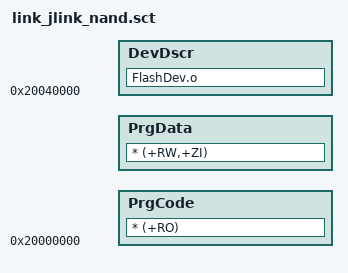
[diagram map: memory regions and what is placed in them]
; Linker Control File (scatter-loading)
;

PRG 0x20000000            ; Programming Functions
{
  PrgCode 0x20000000 +0           ; Code
  {
    * (+RO)
  }
  PrgData +0           ; Data
  {
    * (+RW,+ZI)
  }
  DevDscr 0x20040000
  {
    FlashDev.o
  }
}


